VERSION "hil-engine 0.1"

NS_ :

BS_:

BU_: ENGINE_SIM ECM

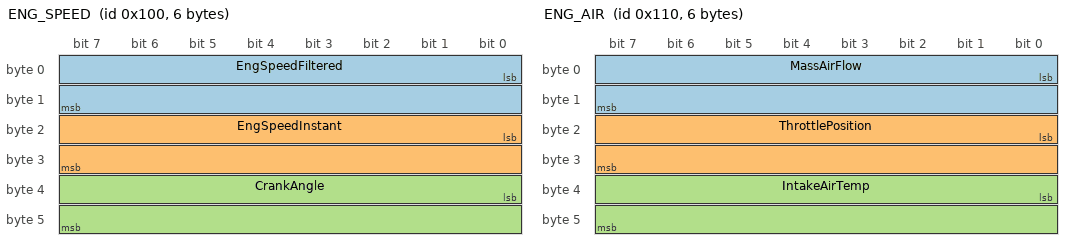
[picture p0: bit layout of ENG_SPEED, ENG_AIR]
BO_ 256 ENG_SPEED: 6 ENGINE_SIM
 SG_ EngSpeedFiltered : 0|16@1+ (0.25,0) [0|16383.75] "rpm" ECM
 SG_ EngSpeedInstant : 16|16@1+ (0.25,0) [0|16383.75] "rpm" ECM
 SG_ CrankAngle : 32|16@1+ (0.02,0) [0|720] "deg" ECM

BO_ 272 ENG_AIR: 6 ENGINE_SIM
 SG_ MassAirFlow : 0|16@1+ (0.01,0) [0|655.35] "g/s" ECM
 SG_ ThrottlePosition : 16|16@1+ (0.01,0) [0|100] "%" ECM
 SG_ IntakeAirTemp : 32|16@1- (0.1,0) [-40|150] "degC" ECM

BO_ 288 ENG_THERMAL: 2 ENGINE_SIM
 SG_ CoolantTemp : 0|16@1- (0.1,0) [-40|150] "degC" ECM

BO_ 304 ENG_COMBUSTION: 4 ENGINE_SIM
 SG_ Lambda : 0|16@1+ (0.001,0) [0|2] "lambda" ECM
 SG_ KnockIntensity : 16|16@1+ (0.0001,0) [0|1] "ratio" ECM

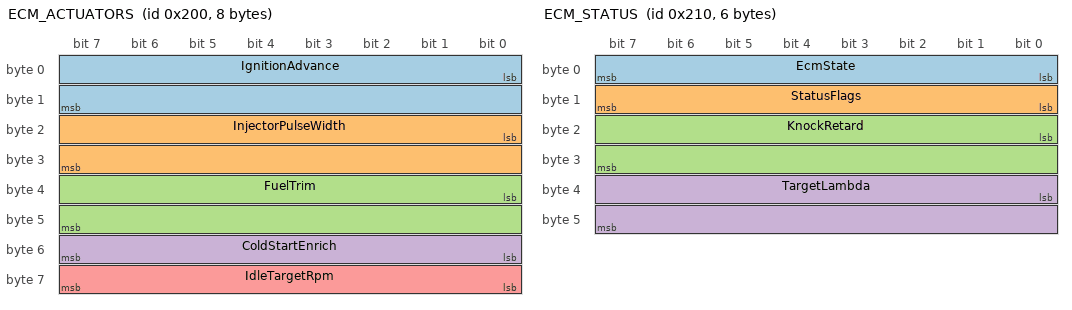
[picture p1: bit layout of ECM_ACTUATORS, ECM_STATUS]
BO_ 512 ECM_ACTUATORS: 8 ECM
 SG_ IgnitionAdvance : 0|16@1- (0.1,0) [-30|50] "degBTDC" ENGINE_SIM
 SG_ InjectorPulseWidth : 16|16@1+ (0.001,0) [0|65.535] "ms" ENGINE_SIM
 SG_ FuelTrim : 32|16@1- (0.01,0) [-25|25] "%" ENGINE_SIM
 SG_ ColdStartEnrich : 48|8@1+ (0.5,0) [0|100] "%" ENGINE_SIM
 SG_ IdleTargetRpm : 56|8@1+ (10,0) [0|2550] "rpm" ENGINE_SIM

BO_ 528 ECM_STATUS: 6 ECM
 SG_ EcmState : 0|8@1+ (1,0) [0|4] "" ENGINE_SIM
 SG_ StatusFlags : 8|8@1+ (1,0) [0|255] "" ENGINE_SIM
 SG_ KnockRetard : 16|16@1- (0.1,0) [0|25] "deg" ENGINE_SIM
 SG_ TargetLambda : 32|16@1+ (0.001,0) [0|2] "lambda" ENGINE_SIM

CM_ BO_ 256 "Crank speed and position. Sent every 10 ms.";
CM_ SG_ 256 EngSpeedInstant "Instantaneous speed including torsional ripple; aliased above idle, use for low-speed/idle diagnostics.";
CM_ SG_ 256 CrankAngle "Engine cycle position 0-720 deg. Aliased on a 10 ms frame above idle; diagnostic only.";
CM_ BO_ 272 "Air path sensors. Sent every 20 ms.";
CM_ BO_ 288 "Slow thermal channel. Sent every 100 ms.";
CM_ BO_ 304 "Combustion-quality sensors (wideband O2 + knock). Sent every 10 ms.";
CM_ BO_ 512 "Actuator commands from the ECM. InjectorPulseWidth is the only physical fueling actuator; FuelTrim and ColdStartEnrich are ECM telemetry already folded into the pulse width. Sent every 10 ms.";
CM_ BO_ 528 "ECM internal state for HIL observability. Sent every 100 ms.";

VAL_ 528 EcmState 0 "INIT" 1 "CRANKING" 2 "WARMUP" 3 "RUNNING" 4 "STALL" ;
